AUTOSAR XML (schema 00049)
package /ISOFT/PlatformComponents/sm/swc
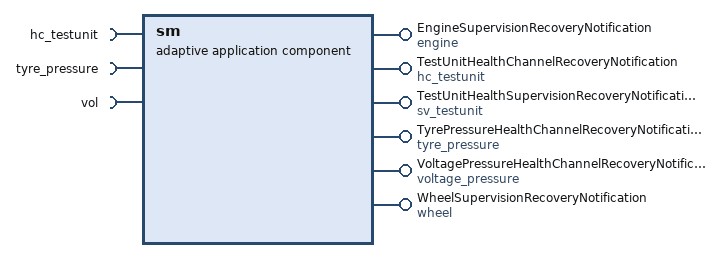
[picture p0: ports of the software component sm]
  adaptive application sw component type sm
    6 x provide port:
      EngineSupervisionRecoveryNotification: provided-interface=engine
      TestUnitHealthChannelRecoveryNotification: provided-interface=hc_testunit
      TestUnitHealthSupervisionRecoveryNotification: provided-interface=sv_testunit
      TyrePressureHealthChannelRecoveryNotification: provided-interface=tyre_pressure
      VoltagePressureHealthChannelRecoveryNotification: provided-interface=voltage_pressure
      WheelSupervisionRecoveryNotification: provided-interface=wheel
    require port hc_testunit: required-interface=hc_testunit
    require port tyre_pressure: required-interface=tyre_pressure
    require port vol: required-interface=vol
